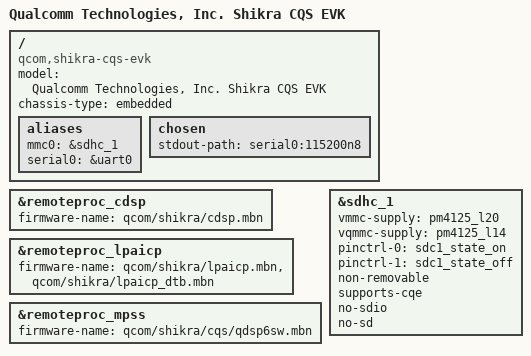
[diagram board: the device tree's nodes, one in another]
// SPDX-License-Identifier: BSD-3-Clause
/*
 * Copyright (c) Qualcomm Technologies, Inc. and/or its subsidiaries.
 */

/dts-v1/;

#include "shikra-cqm-som.dtsi"
#include "shikra-evk.dtsi"

/ {
	model = "Qualcomm Technologies, Inc. Shikra CQS EVK";
	compatible = "qcom,shikra-cqs-evk", "qcom,shikra-cqs-som", "qcom,shikra";
	chassis-type = "embedded";

	aliases {
		mmc0 = &sdhc_1;
		serial0 = &uart0;
	};

	chosen {
		stdout-path = "serial0:115200n8";
	};
};

&remoteproc_cdsp {
	firmware-name = "qcom/shikra/cdsp.mbn";

	status = "okay";
};

&remoteproc_lpaicp {
	firmware-name = "qcom/shikra/lpaicp.mbn",
			"qcom/shikra/lpaicp_dtb.mbn";

	status = "okay";
};

&remoteproc_mpss {
	firmware-name = "qcom/shikra/cqs/qdsp6sw.mbn";

	status = "okay";
};

&sdhc_1 {
	vmmc-supply = <&pm4125_l20>;
	vqmmc-supply = <&pm4125_l14>;

	pinctrl-0 = <&sdc1_state_on>;
	pinctrl-1 = <&sdc1_state_off>;
	pinctrl-names = "default", "sleep";

	non-removable;
	supports-cqe;
	no-sdio;
	no-sd;

	status = "okay";
};
